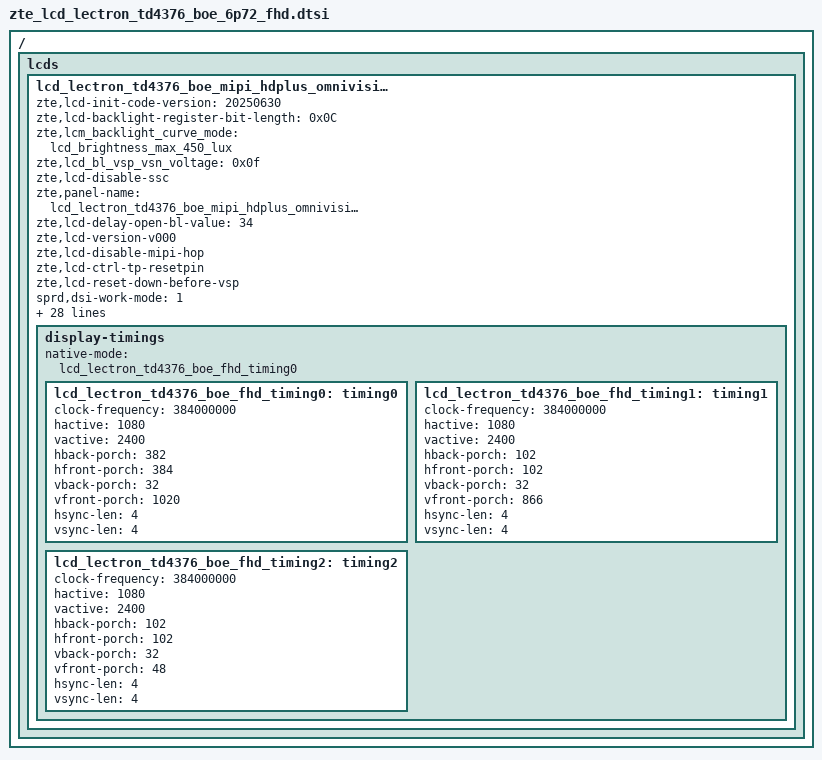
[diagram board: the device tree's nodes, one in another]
/ {
	fragment {
		target-path = "/";
		__overlay__ {
			lcds {
				lcd_lectron_td4376_boe_mipi_hdplus_omnivision: lcd_lectron_td4376_boe_mipi_hdplus_omnivision {
					zte,lcd-init-code-version = "20250630";

					zte,lcd-backlight-register-bit-length = <0x0C>;
					zte,lcm_backlight_curve_mode = "lcd_brightness_max_450_lux";
					zte,lcd_bl_vsp_vsn_voltage = <0x0f>;
					zte,lcd-disable-ssc;
					zte,panel-name = "lcd_lectron_td4376_boe_mipi_hdplus_omnivision";
					zte,lcd-delay-open-bl-value = <34>;
					zte,lcd-version-v000;
					zte,lcd-disable-mipi-hop;
					zte,lcd-ctrl-tp-resetpin;
					zte,lcd-reset-down-before-vsp;

					sprd,dsi-work-mode = <1>;
					sprd,dsi-lane-number = <4>;
					sprd,dsi-color-format = "dsc";
					sprd,phy-bit-clock = <1100000>;
					sprd,phy-escape-clock = <20000>;/* kHz */


					sprd,width-mm = <7008>;
					sprd,height-mm = <15574>;
					sprd,vrr-enabled;
					sprd,vrr-max-layers = <3>;
					sprd,slice-width = <540>;
					sprd,slice-height = <12>;
					sprd,output-bpc = <8>;
					sprd,dsc-enable = <1>;
					sprd,dual-dsi-enable = <0>;

					sprd,esd-check-enable = <1>;/* 0:close , 1:open */
					sprd,esd-check-mode = <1>;/* 0:REG ,1:TE  */
					sprd,esd-check-period = <2000>;
					sprd,esd-check-register = <0x0A>;
					sprd,esd-check-value = <0x9C>;

					sprd,dphy-taget-val = <5>;

					sprd,reset-on-sequence = <1 5>, <0 15>, <1 25>;
					sprd,reset-off-sequence = <0 20>;

					sprd,use-gen-write;
					sprd,initial-command = [
39 00 00 02 B0 00
39 00 00 11 B6 30 6B 00 86 12 0A 13 1A 00 02 0A 0A 02 20 FF FF
39 00 00 05 B7 51 00 00 00
39 00 00 08 B8 57 3D 19 BE 1E 0A 0A
39 00 00 08 B9 6F 3D 28 BE 3C 14 0A
39 00 00 08 BA B5 33 41 BE 64 23 0A
39 00 00 0C BB 44 26 C3 1F 19 06 03 C0 00 00 10
39 00 00 0C BC 32 4C C3 52 32 1F 03 F2 00 00 13
39 00 00 0C BD 24 68 C3 AA 3F 32 03 FF 00 00 25
39 00 00 0D BE 00 00 00 00 00 00 00 00 00 00 00 00
39 00 00 24 C0 00 50 01 2C 14 09 60 00 0C 22 00 08 00 70 00 00 00 00 00 00 00 00 02 01 2C 01 2C 01 2C 00 00 00 00 00 00
39 00 00 63 C1 30 00 00 91 00 00 00 00 22 00 05 20 00 80 FA 40 00 84 0F 00 00 00 00 00 00 00 00 00 00 00 00 00 00 00 00 00 00 00 00 00 00 01 2C 08 08 BF 0B B8 0D 2A 0F A0 11 94 12 5C 1B 58 00 03 00 FF F5 84 7A A0 00 00 00 00 00 00 00 00 00 00 00 00 00 00 00 00 00 00 00 00 00 00 00 00 64 A1 00 01 00 0E 37 D0
39 00 00 A0 C2 00 00 48 12 02 10 03 04 00 00 00 00 00 00 00 00 00 00 00 00 00 00 00 00 00 00 00 00 00 48 04 04 01 00 C0 00 A0 0A 00 00 02 08 00 00 00 00 11 00 A0 0A 04 00 00 00 00 00 00 00 00 00 00 00 00 00 00 00 00 00 00 00 00 00 11 00 00 00 00 00 00 00 00 00 00 00 00 00 00 00 00 00 00 00 00 00 00 00 11 00 00 00 00 00 00 00 00 00 00 00 00 00 00 00 00 00 00 00 00 00 00 00 11 00 00 00 00 00 00 00 00 00 00 00 00 00 00 00 00 00 00 00 00 00 00 00 00 00 00 00 00 00 00 00 00 00 00 00 00 00 00
39 00 00 6D C3 00 00 E0 01 97 E0 08 00 00 00 00 00 00 00 00 00 00 00 00 00 00 00 00 00 00 00 00 00 00 00 00 00 00 00 00 00 00 00 00 00 00 00 00 00 00 00 00 00 00 00 00 00 00 00 00 00 00 00 00 00 00 00 AA AA AA 00 00 00 00 00 00 08 00 06 00 00 02 00 00 C0 00 08 00 50 00 00 01 00 00 C0 00 08 00 50 00 00 01 00 00 C0 00 00 00 00 00 00 00 00
39 00 00 7B C4 00 00 00 61 5F 5D 00 0F 0E 11 10 00 4F BF 00 53 00 BE 4D 4D 44 03 02 51 00 00 00 61 5F 5D 00 0F 0E 11 10 00 4F BF 00 53 00 BE 4D 4D 44 03 02 51 FF FF FF FF FF FF B8 87 7C B8 87 7C 00 30 82 00 30 82 38 00 00 38 00 00 00 00 00 00 00 00 02 00 00 00 02 00 00 00 00 00 09 58 00 00 00 00 00 00 00 00 00 00 00 00 00 00 00 00 00 00 00 00 00 00 00 00 00 00 00 00 00 00 00 00
39 00 00 06 C5 08 00 00 00 00
39 00 00 58 C6 02 0A 08 FC FF FF FF 00 30 13 01 FF 0F 01 05 17 17 17 00 00 00 3F 05 09 28 28 01 05 17 17 17 01 0B 00 00 00 1E 01 00 00 00 00 00 00 20 20 00 00 12 00 00 00 00 00 22 22 00 00 00 00 10 00 01 00 00 00 00 01 00 00 00 00 01 00 00 00 00 05 00 1F 08 FC FF FF FF 01 00
39 00 00 10 CB 20 80 70 00 20 00 00 2D 41 00 00 00 00 00 FF
39 00 00 02 CD 00
39 00 00 24 CE 5D 40 49 53 59 5E 63 68 6E 74 7E 8A 98 A8 BB D0 E7 FF 04 00 04 04 42 40 69 5A 40 00 00 00 00 04 FA 00 00
39 00 00 07 CF 89 00 80 46 61 00
39 00 00 13 D0 CC 1E D5 66 09 B0 00 CF 0F 05 D4 EB 52 FE 09 09 CF 00
39 00 00 3C D1 C4 C4 1B B0 07 07 AA 11 31 22 32 05 77 7B 07 77 3B 78 D2 D2 04 96 10 93 22 22 22 B3 BB 80 00 BB BB 11 00 08 C0 C0 09 77 FF 11 44 11 01 11 01 44 04 44 04 77 77 77 05 05 30 33 FF
39 00 00 18 D4 00 00 00 00 00 00 00 00 00 00 00 00 00 00 00 00 00 00 00 00 00 00 00
39 00 00 50 D7 21 10 52 52 00 50 00 0C 00 50 04 FD 01 00 03 00 05 05 00 03 04 05 00 04 00 08 02 08 06 03 08 04 08 10 0C 0B 0A 0A 0A 07 07 06 06 00 08 08 04 05 09 00 04 04 04 04 04 04 04 02 04 04 04 04 04 04 04 04 04 04 06 06 05 05 05 00 00 00 00 00 00
39 00 00 17 D9 40 99 26 ED 16 6C 16 6C 16 6C 00 14 00 14 00 14 01 0C 00 00 01 00
39 00 00 05 DD 30 06 23 65
39 00 00 0D DE 00 00 00 0F FF 00 00 00 00 10 00 50
39 00 00 0B E6 00 00 00 00 00 00 00 00 00 00
39 00 00 B7 E7 11 00 89 30 80 09 60 04 38 00 0C 02 1C 02 1C 02 00 02 0E 20 01 1F 00 07 0C 08 BB 08 7A 18 00 10 F0 03 0C 20 00 06 0B 0B 33 0E 1C 2A 38 46 54 62 69 70 77 79 7B 7D 7E 01 02 01 00 09 40 09 BE 19 FC 19 FA 19 F8 1A 38 1A 78 1A B6 2A F6 2B 34 2B 74 3B 74 6B F4 00 00 00 00 00 00 11 00 89 30 80 09 60 04 38 00 0C 02 1C 02 1C 02 00 02 0E 20 01 1F 00 07 0C 08 BB 08 7A 18 00 10 F0 03 0C 20 00 06 0B 0B 33 0E 1C 2A 38 46 54 62 69 70 77 79 7B 7D 7E 01 02 01 00 09 40 09 BE 19 FC 19 FA 19 F8 1A 38 1A 78 1A B6 2A F6 2B 34 2B 74 3B 74 6B F4 00 00 00 00 00 00
39 00 00 05 E8 00 30 63 00
39 00 00 26 EA 01 0E 05 80 0B 00 00 00 09 00 01 AA 00 00 00 00 00 00 00 00 04 C2 00 12 00 50 05 00 86 00 00 00 00 00 00 00 00
39 00 00 08 EB 00 00 00 00 01 00 11
39 00 00 0B EC 07 80 00 10 78 0B 00 00 02 3A
39 00 00 21 ED 01 01 02 02 08 08 09 09 00 00 00 00 02 00 00 00 00 0F 00 00 00 00 00 D0 00 00 00 00 00 EC 10 00
39 00 00 64 EE 03 1F 00 00 00 F5 01 00 00 00 00 C2 4F 7D F0 03 00 00 00 00 00 00 00 00 4F 3D F0 01 10 09 09 09 09 00 00 00 00 00 00 00 01 00 00 00 00 00 00 00 00 00 00 00 00 00 00 1F 00 00 00 00 00 00 00 00 00 00 00 00 00 00 00 00 00 00 00 00 00 00 00 00 00 00 00 00 00 00 00 00 00 00 00 00 00 00 00 00 00 00 00
39 00 00 71 EF 00 A0 20 03 60 00 00 00 00 12 12 12 00 00 00 00 00 00 00 00 00 00 A0 20 03 60 12 12 12 00 00 00 00 00 00 10 02 10 02 00 10 00 10 00 0A 06 00 00 00 00 00 0B 00 03 51 00 00 05 00 00 00 00 00 00 00 00 00 00 00 00 00 00 00 00 00 00 00 00 00 00 00 00 00 00 00 00 00 00 00 00 00 00 00 00 00 00 00 00 00 00 00 00 00 00 00 00 00 00 00 00 00 00
39 00 00 08 F9 44 3F 00 8D BF 00 00
39 00 00 02 B0 03
39 00 00 02 B0 04
39 00 00 4D C7 00 00 00 31 00 A4 01 01 01 1E 01 33 01 3A 01 42 01 3E 01 2B 01 80 01 3E 01 81 01 3D 01 AA 01 AB 02 2D 02 A1 02 AF 00 00 00 31 00 A4 01 01 01 1E 01 33 01 3A 01 42 01 3E 01 2B 01 80 01 3E 01 81 01 3D 01 AA 01 AB 02 2D 02 A1 02 AF
39 00 00 02 B0 03
39 00 00 02 35 00
39 00 00 03 51 00 00
39 00 00 02 53 24
05 78 00 01 11
05 14 00 01 29
					];

					sprd,sleep-in-command = [
						39 14 00 03 28 00 00
						39 78 00 03 10 00 00
						];
					sprd,sleep-out-command = [
						39 78 00 03 11 00 00
						39 14 00 03 29 00 00
						];
					display-timings {
						native-mode = <&lcd_lectron_td4376_boe_fhd_timing0>;
						lcd_lectron_td4376_boe_fhd_timing0: timing0 {
							clock-frequency = <384000000>;
							hactive = <1080>;
							vactive = <2400>;
							hback-porch = <382>;
							hfront-porch = <384>;
							vback-porch = <32>;
							vfront-porch = <1020>;
							hsync-len = <4>;
							vsync-len = <4>;
						};
						lcd_lectron_td4376_boe_fhd_timing1: timing1 {
							clock-frequency = <384000000>;
							hactive = <1080>;
							vactive = <2400>;
							hback-porch = <102>;
							hfront-porch = <102>;
							vback-porch = <32>;
							vfront-porch = <866>;
							hsync-len = <4>;
							vsync-len = <4>;
						};
						lcd_lectron_td4376_boe_fhd_timing2: timing2 {
							clock-frequency = <384000000>;
							hactive = <1080>;
							vactive = <2400>;
							hback-porch = <102>;
							hfront-porch = <102>;
							vback-porch = <32>;
							vfront-porch = <48>;
							hsync-len = <4>;
							vsync-len = <4>;
						};
					};
				};
			};
		};
	};
};
